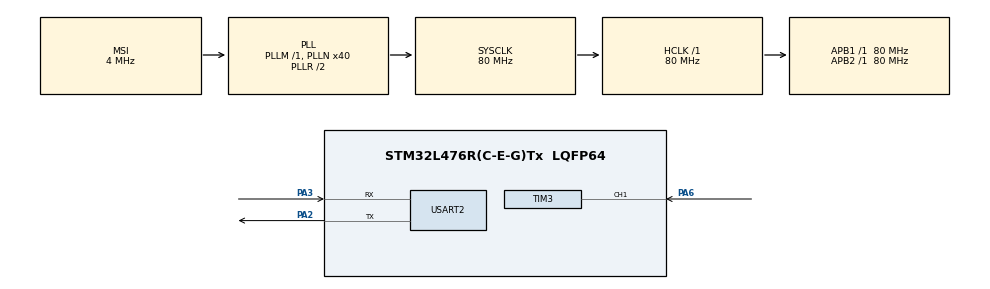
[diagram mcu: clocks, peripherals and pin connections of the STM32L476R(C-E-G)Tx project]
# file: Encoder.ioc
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Mcu.Family=STM32L4
Mcu.Name=STM32L476R(C-E-G)Tx
Mcu.Package=LQFP64
NVIC.PriorityGroup=NVIC_PRIORITYGROUP_4
NVIC.TIM3_IRQn=true\:10\:0\:true\:false\:true\:true\:true\:true
PA13\ (JTMS-SWDIO).Mode=Serial_Wire
PA13\ (JTMS-SWDIO).Signal=SYS_JTMS-SWDIO
PA14\ (JTCK-SWCLK).Mode=Serial_Wire
PA14\ (JTCK-SWCLK).Signal=SYS_JTCK-SWCLK
PA2.Mode=Asynchronous
PA2.Signal=USART2_TX
PA3.Mode=Asynchronous
PA3.Signal=USART2_RX
PA6.Signal=S_TIM3_CH1
ProjectManager.HeapSize=0x200
ProjectManager.StackSize=0x400
ProjectManager.TargetToolchain=STM32CubeIDE
RCC.AHBFreq_Value=80000000
RCC.APB1Freq_Value=80000000
RCC.APB1TimFreq_Value=80000000
RCC.APB2Freq_Value=80000000
RCC.APB2TimFreq_Value=80000000
RCC.CortexFreq_Value=80000000
RCC.HCLKFreq_Value=80000000
RCC.HSE_VALUE=8000000
RCC.HSI_VALUE=16000000
RCC.LSE_VALUE=32768
RCC.MSI_VALUE=4000000
RCC.PLLN=40
RCC.SYSCLKFreq_VALUE=80000000
RCC.SYSCLKSource=RCC_SYSCLKSOURCE_PLLCLK
RCC.VCOOutputFreq_Value=160000000
SH.S_TIM3_CH1.0=TIM3_CH1,TriggerSource_TI1ED
SH.S_TIM3_CH1.1=TIM3_CH1,Input_Capture1_from_TI1
TIM3.Channel-Input_Capture1_from_TI1=TIM_CHANNEL_1
TIM3.ICFilter_CH1=15
TIM3.Prescaler=7999
USART2.VirtualMode-Asynchronous=VM_ASYNC
VP_TIM3_VS_ClockSourceINT.Mode=Internal
VP_TIM3_VS_ControllerModeReset.Mode=Reset Mode
board=custom

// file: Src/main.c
/* USER CODE BEGIN Header */
/**
  ******************************************************************************
  * @file           : main.c
  * @brief          : Main program body
  ******************************************************************************
  * @attention
  *
  * Copyright (c) 2023 STMicroelectronics.
  * All rights reserved.
  *
  * This software is licensed under terms that can be found in the LICENSE file
  * in the root directory of this software component.
  * If no LICENSE file comes with this software, it is provided AS-IS.
  *
  ******************************************************************************
  */
/* USER CODE END Header */
#include "main.h"

/* USER CODE BEGIN Includes */
#include <stdio.h>
/* USER CODE END Includes */

TIM_HandleTypeDef htim3;

UART_HandleTypeDef huart2;

void SystemClock_Config(void);
static void MX_GPIO_Init(void);
static void MX_TIM3_Init(void);
static void MX_USART2_UART_Init(void);

/* USER CODE BEGIN 0 */
int __io_putchar(int ch)
{
  if (ch == '\n') {
    __io_putchar('\r');
  }

  HAL_UART_Transmit(&huart2, (uint8_t*)&ch, 1, HAL_MAX_DELAY);

  return 1;
}

volatile uint32_t captured_value;

void HAL_TIM_IC_CaptureCallback(TIM_HandleTypeDef *htim)
{
  if (htim == &htim3) {
    switch (HAL_TIM_GetActiveChannel(&htim3)) {
      case HAL_TIM_ACTIVE_CHANNEL_1:
        captured_value = HAL_TIM_ReadCapturedValue(htim, TIM_CHANNEL_1);
        break;
      default:
        break;
    }
  }
}
/* USER CODE END 0 */

int main(void)
{

  /* MCU Configuration--------------------------------------------------------*/

  /* Reset of all peripherals, Initializes the Flash interface and the Systick. */
  HAL_Init();

  /* Configure the system clock */
  SystemClock_Config();

  /* Initialize all configured peripherals */
  MX_GPIO_Init();
  MX_TIM3_Init();
  MX_USART2_UART_Init();

  /* Infinite loop */
  /* USER CODE BEGIN WHILE */
  HAL_TIM_Base_Start(&htim3);
  HAL_TIM_IC_Start_IT(&htim3, TIM_CHANNEL_1);
  uint32_t old_value;
  while (1)
  {
	  uint32_t value = __HAL_TIM_GET_COUNTER(&htim3);
	  if(captured_value != 0){
		  printf("value = %lu\n", captured_value);
		  captured_value = 0;
	  }
    /* USER CODE END WHILE */

  }
}

void SystemClock_Config(void)
{
  RCC_OscInitTypeDef RCC_OscInitStruct = {0};
  RCC_ClkInitTypeDef RCC_ClkInitStruct = {0};

  /** Configure the main internal regulator output voltage
  */
  if (HAL_PWREx_ControlVoltageScaling(PWR_REGULATOR_VOLTAGE_SCALE1) != HAL_OK)
  {
    Error_Handler();
  }

  /** Initializes the RCC Oscillators according to the specified parameters
  * in the RCC_OscInitTypeDef structure.
  */
  RCC_OscInitStruct.OscillatorType = RCC_OSCILLATORTYPE_MSI;
  RCC_OscInitStruct.MSIState = RCC_MSI_ON;
  RCC_OscInitStruct.MSICalibrationValue = 0;
  RCC_OscInitStruct.MSIClockRange = RCC_MSIRANGE_6;
  RCC_OscInitStruct.PLL.PLLState = RCC_PLL_ON;
  RCC_OscInitStruct.PLL.PLLSource = RCC_PLLSOURCE_MSI;
  RCC_OscInitStruct.PLL.PLLM = 1;
  RCC_OscInitStruct.PLL.PLLN = 40;
  RCC_OscInitStruct.PLL.PLLP = RCC_PLLP_DIV7;
  RCC_OscInitStruct.PLL.PLLQ = RCC_PLLQ_DIV2;
  RCC_OscInitStruct.PLL.PLLR = RCC_PLLR_DIV2;
  if (HAL_RCC_OscConfig(&RCC_OscInitStruct) != HAL_OK)
  {
    Error_Handler();
  }

  /** Initializes the CPU, AHB and APB buses clocks
  */
  RCC_ClkInitStruct.ClockType = RCC_CLOCKTYPE_HCLK|RCC_CLOCKTYPE_SYSCLK
                              |RCC_CLOCKTYPE_PCLK1|RCC_CLOCKTYPE_PCLK2;
  RCC_ClkInitStruct.SYSCLKSource = RCC_SYSCLKSOURCE_PLLCLK;
  RCC_ClkInitStruct.AHBCLKDivider = RCC_SYSCLK_DIV1;
  RCC_ClkInitStruct.APB1CLKDivider = RCC_HCLK_DIV1;
  RCC_ClkInitStruct.APB2CLKDivider = RCC_HCLK_DIV1;

  if (HAL_RCC_ClockConfig(&RCC_ClkInitStruct, FLASH_LATENCY_4) != HAL_OK)
  {
    Error_Handler();
  }
}

static void MX_TIM3_Init(void)
{

  TIM_ClockConfigTypeDef sClockSourceConfig = {0};
  TIM_SlaveConfigTypeDef sSlaveConfig = {0};
  TIM_MasterConfigTypeDef sMasterConfig = {0};
  TIM_IC_InitTypeDef sConfigIC = {0};

  htim3.Instance = TIM3;
  htim3.Init.Prescaler = 7999;
  htim3.Init.CounterMode = TIM_COUNTERMODE_UP;
  htim3.Init.Period = 65535;
  htim3.Init.ClockDivision = TIM_CLOCKDIVISION_DIV1;
  htim3.Init.AutoReloadPreload = TIM_AUTORELOAD_PRELOAD_DISABLE;
  if (HAL_TIM_Base_Init(&htim3) != HAL_OK)
  {
    Error_Handler();
  }
  sClockSourceConfig.ClockSource = TIM_CLOCKSOURCE_INTERNAL;
  if (HAL_TIM_ConfigClockSource(&htim3, &sClockSourceConfig) != HAL_OK)
  {
    Error_Handler();
  }
  if (HAL_TIM_IC_Init(&htim3) != HAL_OK)
  {
    Error_Handler();
  }
  sSlaveConfig.SlaveMode = TIM_SLAVEMODE_RESET;
  sSlaveConfig.InputTrigger = TIM_TS_TI1F_ED;
  sSlaveConfig.TriggerPolarity = TIM_INPUTCHANNELPOLARITY_RISING;
  sSlaveConfig.TriggerFilter = 0;
  if (HAL_TIM_SlaveConfigSynchro(&htim3, &sSlaveConfig) != HAL_OK)
  {
    Error_Handler();
  }
  sMasterConfig.MasterOutputTrigger = TIM_TRGO_RESET;
  sMasterConfig.MasterSlaveMode = TIM_MASTERSLAVEMODE_DISABLE;
  if (HAL_TIMEx_MasterConfigSynchronization(&htim3, &sMasterConfig) != HAL_OK)
  {
    Error_Handler();
  }
  sConfigIC.ICPolarity = TIM_INPUTCHANNELPOLARITY_RISING;
  sConfigIC.ICSelection = TIM_ICSELECTION_DIRECTTI;
  sConfigIC.ICPrescaler = TIM_ICPSC_DIV1;
  sConfigIC.ICFilter = 15;
  if (HAL_TIM_IC_ConfigChannel(&htim3, &sConfigIC, TIM_CHANNEL_1) != HAL_OK)
  {
    Error_Handler();
  }

}

static void MX_USART2_UART_Init(void)
{

  huart2.Instance = USART2;
  huart2.Init.BaudRate = 115200;
  huart2.Init.WordLength = UART_WORDLENGTH_8B;
  huart2.Init.StopBits = UART_STOPBITS_1;
  huart2.Init.Parity = UART_PARITY_NONE;
  huart2.Init.Mode = UART_MODE_TX_RX;
  huart2.Init.HwFlowCtl = UART_HWCONTROL_NONE;
  huart2.Init.OverSampling = UART_OVERSAMPLING_16;
  huart2.Init.OneBitSampling = UART_ONE_BIT_SAMPLE_DISABLE;
  huart2.AdvancedInit.AdvFeatureInit = UART_ADVFEATURE_NO_INIT;
  if (HAL_UART_Init(&huart2) != HAL_OK)
  {
    Error_Handler();
  }

}

static void MX_GPIO_Init(void)
{

  /* GPIO Ports Clock Enable */
  __HAL_RCC_GPIOA_CLK_ENABLE();

}

void Error_Handler(void)
{
  __disable_irq();
  while (1)
  {
  }
}
